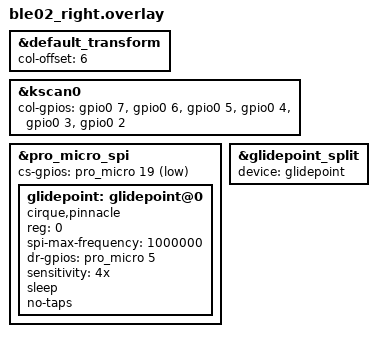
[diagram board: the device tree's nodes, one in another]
#include "ble02.dtsi"

&default_transform {
    col-offset = <6>;
};

&kscan0 {
    col-gpios
        = <&gpio0 7 GPIO_ACTIVE_HIGH>
        , <&gpio0 6  GPIO_ACTIVE_HIGH>
        , <&gpio0 5  GPIO_ACTIVE_HIGH>
        , <&gpio0 4  GPIO_ACTIVE_HIGH>
        , <&gpio0 3  GPIO_ACTIVE_HIGH>
        , <&gpio0 2  GPIO_ACTIVE_HIGH>
        ;
};

&pro_micro_spi {
    status = "okay";
    cs-gpios = <&pro_micro 19 GPIO_ACTIVE_LOW>;

    glidepoint: glidepoint@0 {
        compatible = "cirque,pinnacle";
        reg = <0>;
        spi-max-frequency = <1000000>;
        status = "okay";
        dr-gpios = <&pro_micro 5 (GPIO_ACTIVE_HIGH)>;

        sensitivity = "4x";
        sleep;
        no-taps;
    };
};


&glidepoint_split {
    device = <&glidepoint>;
};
